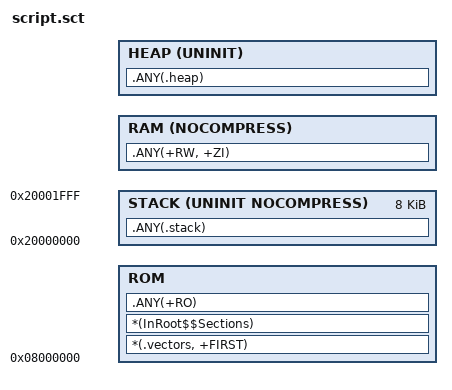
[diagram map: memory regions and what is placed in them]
/*******************************************************************************
@file     stm32f0xx.sct
@author   Rajmund Szymanski
@date     21.05.2016
@brief    Scatter file for STM32F051R8 device with 64KB FLASH and 8KB RAM
*******************************************************************************/

FLASH 0x08000000 0x00010000
{
	ROM +0
	{
		*(.vectors, +FIRST)
		*(InRoot$$Sections)
		.ANY(+RO)
	}

	STACK 0x20000000 UNINIT NOCOMPRESS 0x00002000
	{
		.ANY(.stack)
	}

	RAM ALIGNEXPR(+0, 8) NOCOMPRESS
	{
		.ANY(+RW, +ZI)
	}

	HEAP ALIGNEXPR(+0, 8) UNINIT
	{
		.ANY(.heap)
	}
}
